# jbr_MDR1986VE1T register map
Registers are 32-bit, access not given, no defined reset value unless marked. A register's access mark holds for its fields unless they carry their own. Addresses are absolute; registers are grouped by the start of their names; [hi:lo] are bit positions; {n}, {i} and the like mark numbered series.

## UART2
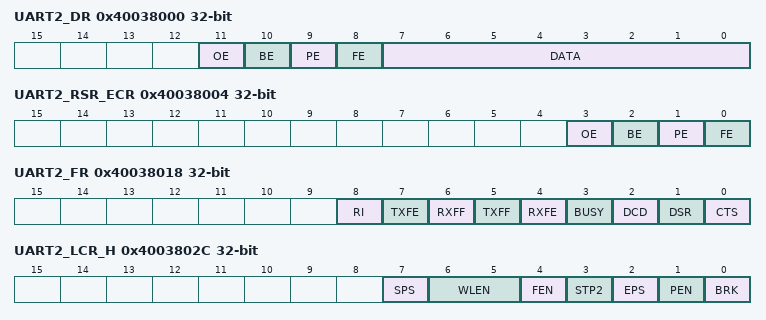
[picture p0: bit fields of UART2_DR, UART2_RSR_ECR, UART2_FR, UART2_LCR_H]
0x40038000 UART2_DR
  [11] OE, [10] BE, [9] PE, [8] FE, [7:0] DATA
0x40038004 UART2_RSR_ECR
  [3] OE, [2] BE, [1] PE, [0] FE
0x40038018 UART2_FR
  [8] RI, [7] TXFE, [6] RXFF, [5] TXFF, [4] RXFE, [3] BUSY, [2] DCD, [1] DSR, [0] CTS
0x40038020 UART2_ILPR
  [7:0] ILPDVSR
0x40038024 UART2_IBRD
  [15:0] BAUDDIV_INT
0x40038028 UART2_FBRD
  [5:0] BAUDDIV_FRAC
0x4003802C UART2_LCR_H
  [7] SPS, [6:5] WLEN, [4] FEN, [3] STP2, [2] EPS, [1] PEN, [0] BRK
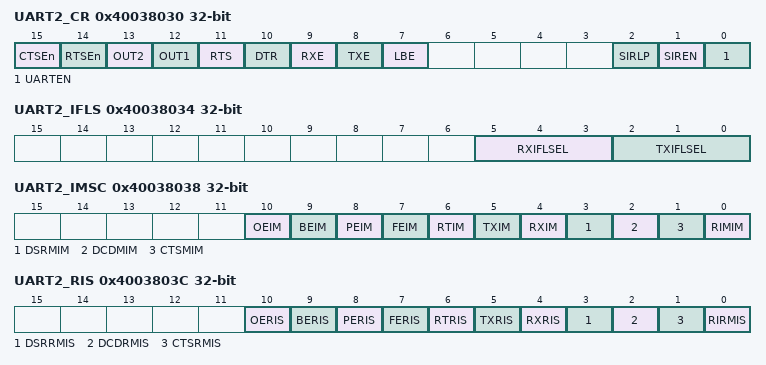
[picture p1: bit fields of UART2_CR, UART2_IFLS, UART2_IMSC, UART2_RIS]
0x40038030 UART2_CR
  [15] CTSEn, [14] RTSEn, [13] OUT2, [12] OUT1, [11] RTS, [10] DTR, [9] RXE, [8] TXE, [7] LBE, [2] SIRLP, [1] SIREN, [0] UARTEN
0x40038034 UART2_IFLS
  [5:3] RXIFLSEL, [2:0] TXIFLSEL
0x40038038 UART2_IMSC
  [10] OEIM, [9] BEIM, [8] PEIM, [7] FEIM, [6] RTIM, [5] TXIM, [4] RXIM, [3] DSRMIM, [2] DCDMIM, [1] CTSMIM, [0] RIMIM
0x4003803C UART2_RIS
  [10] OERIS, [9] BERIS, [8] PERIS, [7] FERIS, [6] RTRIS, [5] TXRIS, [4] RXRIS, [3] DSRRMIS, [2] DCDRMIS, [1] CTSRMIS, [0] RIRMIS
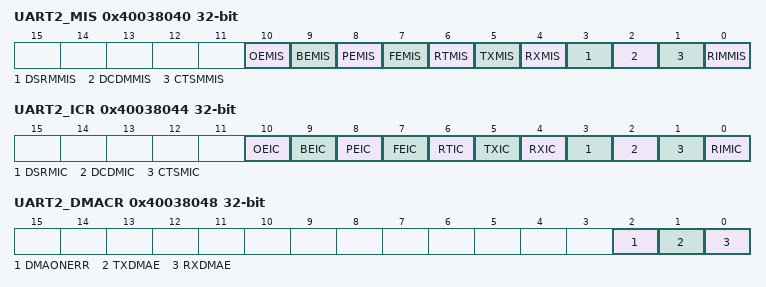
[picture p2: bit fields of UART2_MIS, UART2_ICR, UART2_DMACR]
0x40038040 UART2_MIS
  [10] OEMIS, [9] BEMIS, [8] PEMIS, [7] FEMIS, [6] RTMIS, [5] TXMIS, [4] RXMIS, [3] DSRMMIS, [2] DCDMMIS, [1] CTSMMIS, [0] RIMMIS
0x40038044 UART2_ICR
  [10] OEIC, [9] BEIC, [8] PEIC, [7] FEIC, [6] RTIC, [5] TXIC, [4] RXIC, [3] DSRMIC, [2] DCDMIC, [1] CTSMIC, [0] RIMIC
0x40038048 UART2_DMACR
  [2] DMAONERR, [1] TXDMAE, [0] RXDMAE

## ADC1
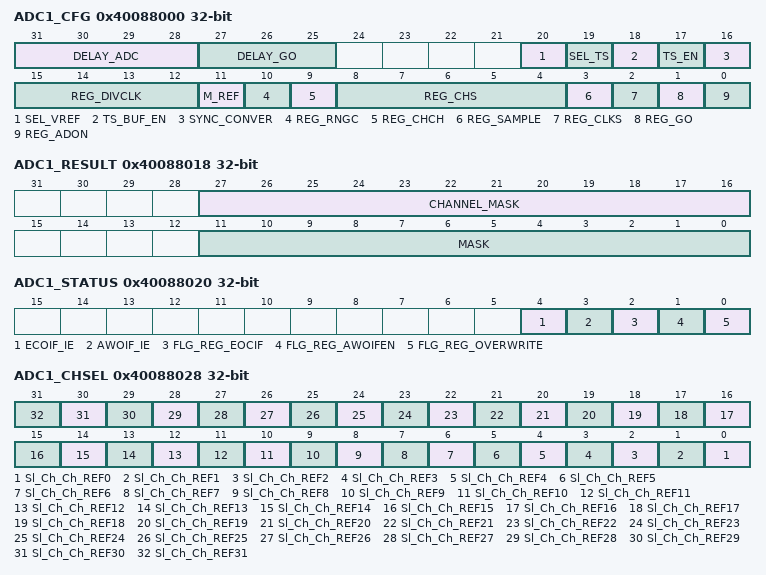
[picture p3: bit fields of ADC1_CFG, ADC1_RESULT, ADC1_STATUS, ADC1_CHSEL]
0x40088000 ADC1_CFG
  [31:28] DELAY_ADC, [27:25] DELAY_GO, [20] SEL_VREF, [19] SEL_TS, [18] TS_BUF_EN, [17] TS_EN, [16] SYNC_CONVER, [15:12] REG_DIVCLK, [11] M_REF, [10] REG_RNGC, [9] REG_CHCH, [8:4] REG_CHS, [3] REG_SAMPLE, [2] REG_CLKS, [1] REG_GO, [0] REG_ADON
0x40088008 ADC1_H_LEVEL
0x40088010 ADC1_L_LEVEL
0x40088018 ADC1_RESULT
  [27:16] CHANNEL_MASK, [11:0] MASK
0x40088020 ADC1_STATUS
  [4] ECOIF_IE, [3] AWOIF_IE, [2] FLG_REG_EOCIF, [1] FLG_REG_AWOIFEN, [0] FLG_REG_OVERWRITE
0x40088028 ADC1_CHSEL
  [n] Sl_Ch_Ch_REF{n} (n=0..31)
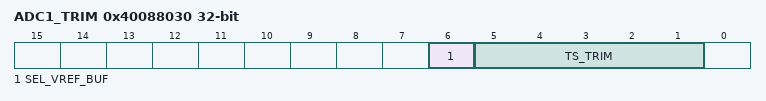
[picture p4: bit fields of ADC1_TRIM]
0x40088030 ADC1_TRIM
  [6] SEL_VREF_BUF, [5:1] TS_TRIM

## GPIOA
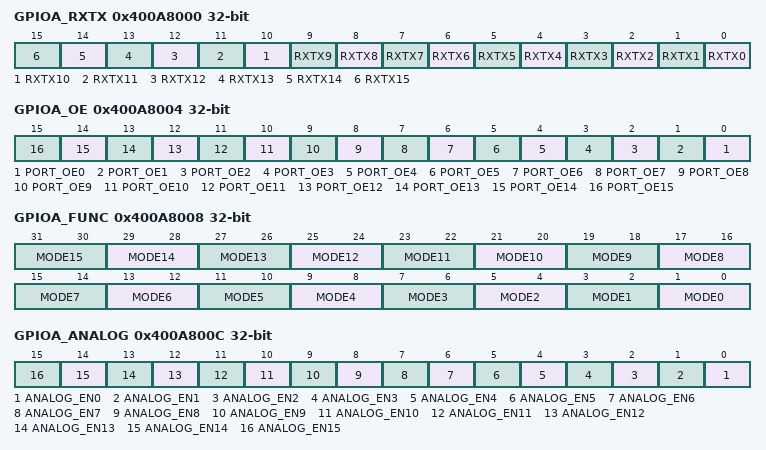
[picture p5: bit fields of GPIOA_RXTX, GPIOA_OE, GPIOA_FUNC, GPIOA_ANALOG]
0x400A8000 GPIOA_RXTX
  [n] RXTX{n} (n=0..15)
0x400A8004 GPIOA_OE
  [n] PORT_OE{n} (n=0..15)
0x400A8008 GPIOA_FUNC
  [2n+1:2n] MODE{n} (n=0..15)
0x400A800C GPIOA_ANALOG
  [n] ANALOG_EN{n} (n=0..15)
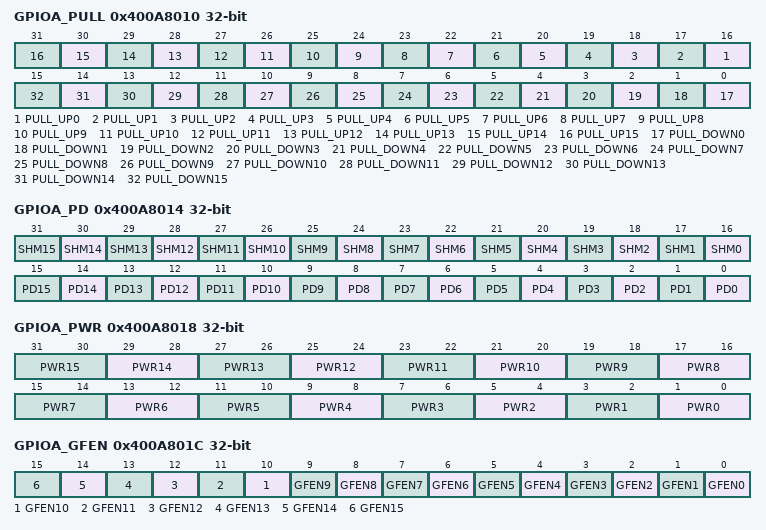
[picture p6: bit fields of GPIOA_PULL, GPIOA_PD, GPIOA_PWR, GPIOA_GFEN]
0x400A8010 GPIOA_PULL
  [n+16] PULL_UP{n} (n=0..15), [n] PULL_DOWN{n} (n=0..15)
0x400A8014 GPIOA_PD
  [n+16] SHM{n} (n=0..15), [n] PD{n} (n=0..15)
0x400A8018 GPIOA_PWR
  [2n+1:2n] PWR{n} (n=0..15)
0x400A801C GPIOA_GFEN
  [n] GFEN{n} (n=0..15)
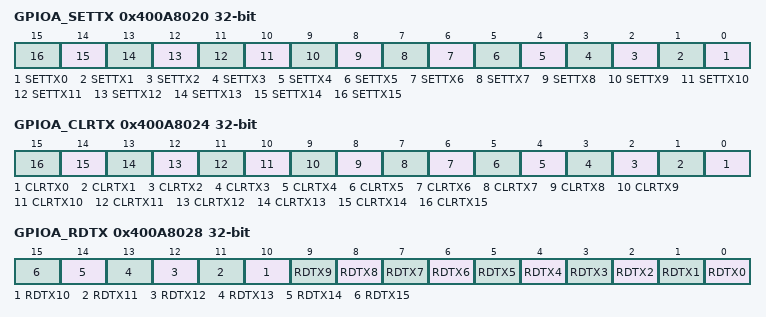
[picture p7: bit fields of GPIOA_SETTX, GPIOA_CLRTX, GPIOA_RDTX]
0x400A8020 GPIOA_SETTX
  [n] SETTX{n} (n=0..15)
0x400A8024 GPIOA_CLRTX
  [n] CLRTX{n} (n=0..15)
0x400A8028 GPIOA_RDTX
  [n] RDTX{n} (n=0..15)

## GPIOB
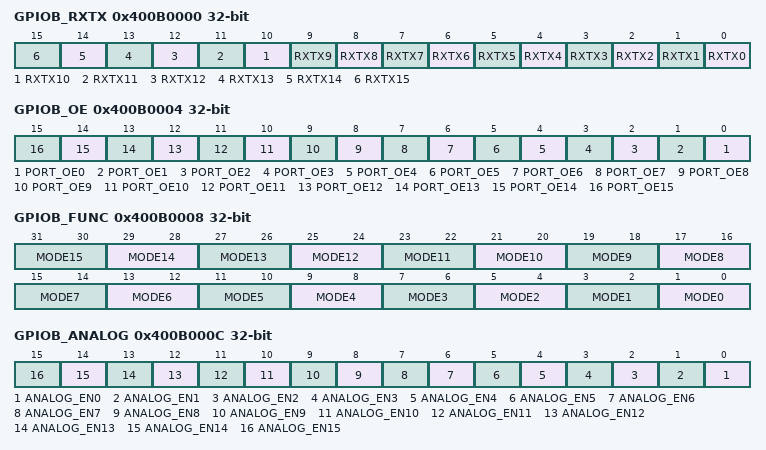
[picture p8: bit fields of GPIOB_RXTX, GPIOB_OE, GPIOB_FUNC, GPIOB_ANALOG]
0x400B0000 GPIOB_RXTX
  [n] RXTX{n} (n=0..15)
0x400B0004 GPIOB_OE
  [n] PORT_OE{n} (n=0..15)
0x400B0008 GPIOB_FUNC
  [2n+1:2n] MODE{n} (n=0..15)
0x400B000C GPIOB_ANALOG
  [n] ANALOG_EN{n} (n=0..15)
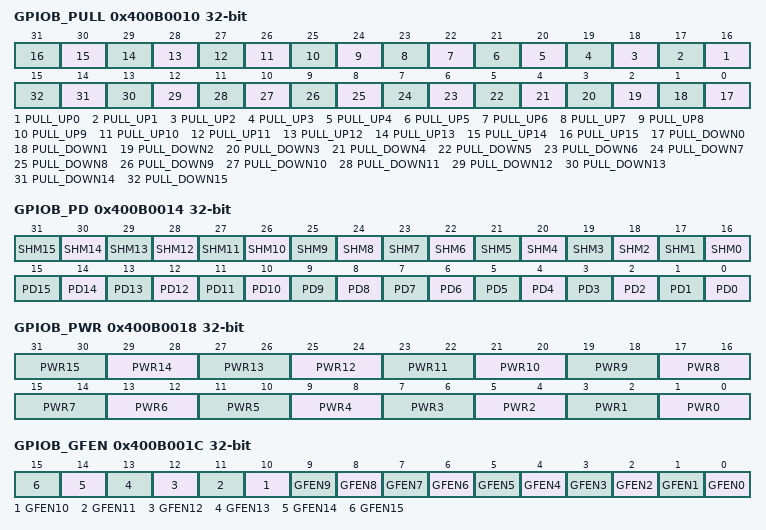
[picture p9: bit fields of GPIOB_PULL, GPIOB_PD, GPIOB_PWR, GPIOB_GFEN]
0x400B0010 GPIOB_PULL
  [n+16] PULL_UP{n} (n=0..15), [n] PULL_DOWN{n} (n=0..15)
0x400B0014 GPIOB_PD
  [n+16] SHM{n} (n=0..15), [n] PD{n} (n=0..15)
0x400B0018 GPIOB_PWR
  [2n+1:2n] PWR{n} (n=0..15)
0x400B001C GPIOB_GFEN
  [n] GFEN{n} (n=0..15)
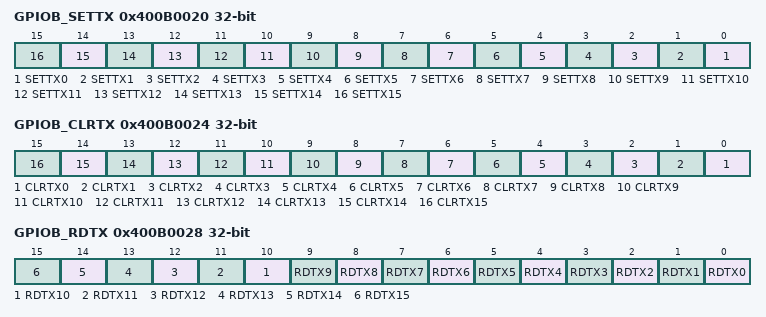
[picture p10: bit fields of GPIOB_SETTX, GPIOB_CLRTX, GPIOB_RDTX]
0x400B0020 GPIOB_SETTX
  [n] SETTX{n} (n=0..15)
0x400B0024 GPIOB_CLRTX
  [n] CLRTX{n} (n=0..15)
0x400B0028 GPIOB_RDTX
  [n] RDTX{n} (n=0..15)

## GPIOC
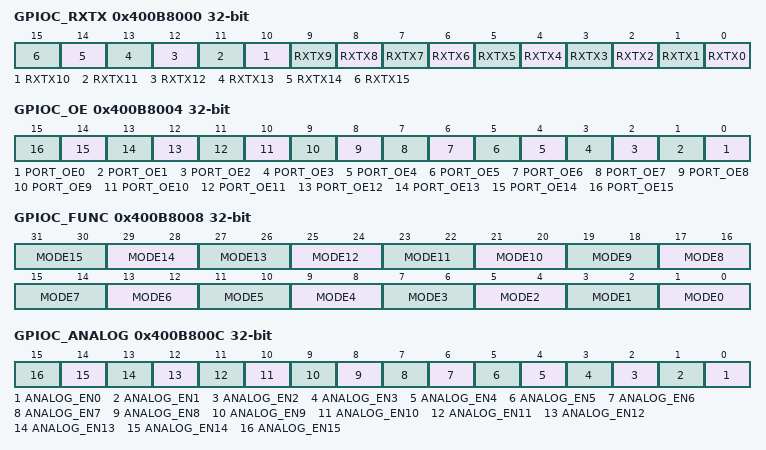
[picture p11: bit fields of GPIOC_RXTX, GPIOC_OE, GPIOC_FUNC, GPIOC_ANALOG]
0x400B8000 GPIOC_RXTX
  [n] RXTX{n} (n=0..15)
0x400B8004 GPIOC_OE
  [n] PORT_OE{n} (n=0..15)
0x400B8008 GPIOC_FUNC
  [2n+1:2n] MODE{n} (n=0..15)
0x400B800C GPIOC_ANALOG
  [n] ANALOG_EN{n} (n=0..15)
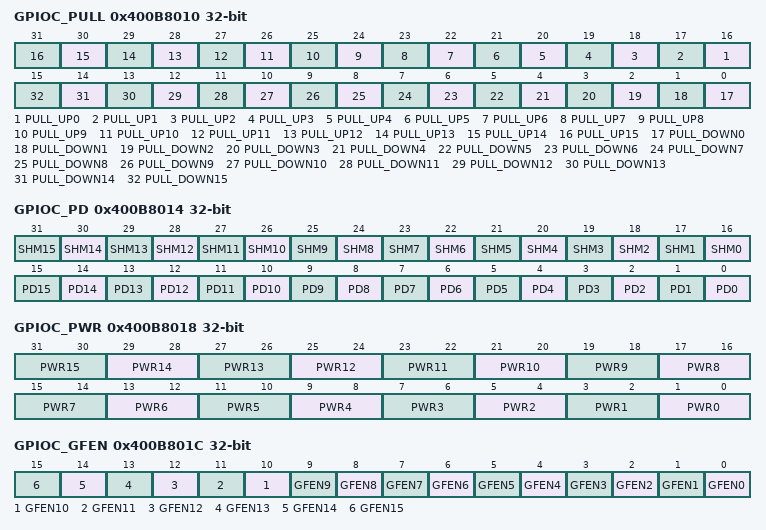
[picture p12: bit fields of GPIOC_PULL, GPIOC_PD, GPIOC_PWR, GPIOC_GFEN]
0x400B8010 GPIOC_PULL
  [n+16] PULL_UP{n} (n=0..15), [n] PULL_DOWN{n} (n=0..15)
0x400B8014 GPIOC_PD
  [n+16] SHM{n} (n=0..15), [n] PD{n} (n=0..15)
0x400B8018 GPIOC_PWR
  [2n+1:2n] PWR{n} (n=0..15)
0x400B801C GPIOC_GFEN
  [n] GFEN{n} (n=0..15)
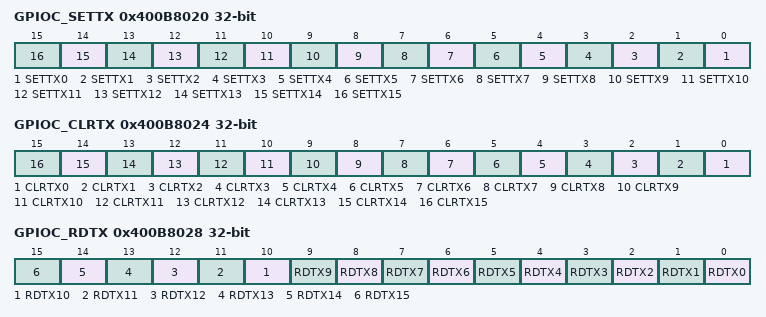
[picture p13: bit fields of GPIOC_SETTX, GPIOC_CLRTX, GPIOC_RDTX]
0x400B8020 GPIOC_SETTX
  [n] SETTX{n} (n=0..15)
0x400B8024 GPIOC_CLRTX
  [n] CLRTX{n} (n=0..15)
0x400B8028 GPIOC_RDTX
  [n] RDTX{n} (n=0..15)
